# nrf9220_sysctrl register map
Vendor: Nordic Semiconductor; Series: nRF92; File version: 1
Registers are 32-bit, read-write, reset 0x0 unless marked. A register's access mark holds for its fields unless they carry their own. Offsets are from the block's base; [hi:lo] are bit positions; {n}, {i} and the like mark numbered series; 'fields as' and 'values as' point back to an identical list.

## HVBUCK1V8 — Saana HVBUCK register map HVBUCK register map for digital part HVBUCK register map for analog part 0
Base 0x5F97B000
Same registers: HVBUCK1V1 0x5F97C000
0x00 TASKS_START wo — This task will start IP
  [0] TASKS_START
    1=Trigger task
0x04 TASKS_STOP wo — This task will stop IP
  [0] TASKS_STOP
    1=Trigger task
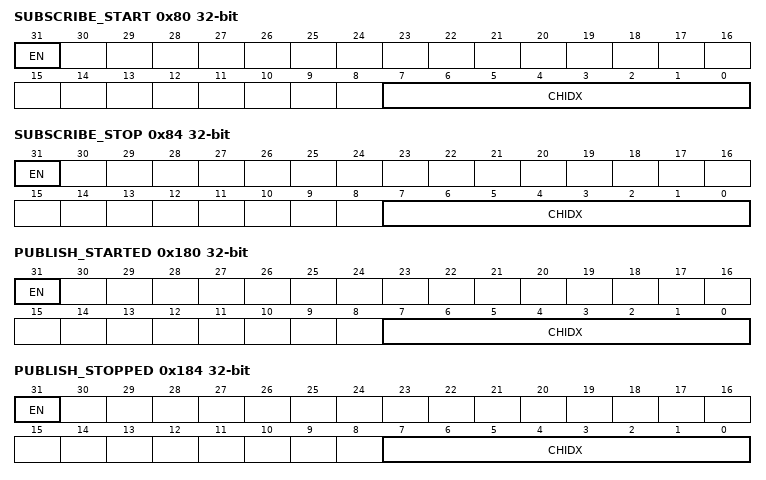
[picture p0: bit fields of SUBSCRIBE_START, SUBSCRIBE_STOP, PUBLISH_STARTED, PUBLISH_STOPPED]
0x80 SUBSCRIBE_START — Subscribe configuration for task START
  [31] EN
    0=Disabled (Disable subscription); 1=Enabled (Enable subscription)
  [7:0] CHIDX — DPPI channel that task START will subscribe to
0x84 SUBSCRIBE_STOP — Subscribe configuration for task STOP
  [31] EN
    values as SUBSCRIBE_START.EN
  [7:0] CHIDX — DPPI channel that task STOP will subscribe to
0x100 EVENTS_STARTED — IP was started
  [0] EVENTS_STARTED
    0=NotGenerated (Event not generated); 1=Generated (Event generated)
0x104 EVENTS_STOPPED — IP was stopped
  [0] EVENTS_STOPPED
    values as EVENTS_STARTED.EVENTS_STARTED
0x180 PUBLISH_STARTED — Publish configuration for event STARTED
  [31] EN
    0=Disabled (Disable publishing); 1=Enabled (Enable publishing)
  [7:0] CHIDX — DPPI channel that event STARTED will publish to
0x184 PUBLISH_STOPPED — Publish configuration for event STOPPED
  [31] EN
    values as PUBLISH_STARTED.EN
  [7:0] CHIDX — DPPI channel that event STOPPED will publish to
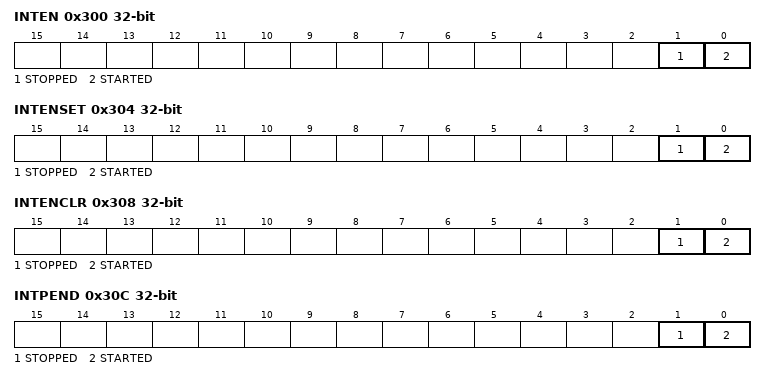
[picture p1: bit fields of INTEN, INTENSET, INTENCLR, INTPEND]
0x300 INTEN — Enable or disable interrupt
  [1] STOPPED — Enable or disable interrupt for event STOPPED
    0=Disabled; 1=Enabled
  [0] STARTED — Enable or disable interrupt for event STARTED
    0=Disabled; 1=Enabled
0x304 INTENSET — Enable interrupt
  [1] STOPPED — Write '1' to enable interrupt for event STOPPED
    on read: 0=Disabled (Read: Disabled); 1=Enabled (Read: Enabled) | on write: 1=Set (Enable)
  [0] STARTED — Write '1' to enable interrupt for event STARTED
    values as STOPPED
0x308 INTENCLR — Disable interrupt
  [1] STOPPED — Write '1' to disable interrupt for event STOPPED
    on read: 0=Disabled (Read: Disabled); 1=Enabled (Read: Enabled) | on write: 1=Clear (Disable)
  [0] STARTED — Write '1' to disable interrupt for event STARTED
    values as STOPPED
0x30C INTPEND ro — Pending interrupts
  [1] STOPPED — Read pending status of interrupt for event STOPPED
    on read: 0=NotPending (Read: Not pending); 1=Pending (Read: Pending)
  [0] STARTED — Read pending status of interrupt for event STARTED
    values as STOPPED
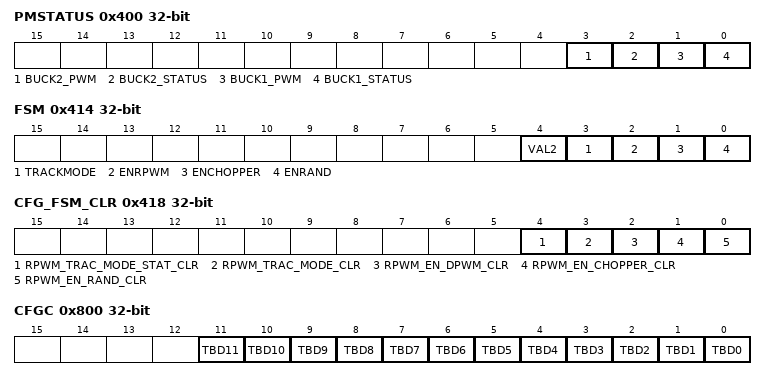
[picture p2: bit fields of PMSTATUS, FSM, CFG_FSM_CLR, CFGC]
0x400 PMSTATUS ro — Power management system status
  [3] BUCK2_PWM — Indicates if BUCK1 is in PWM mode
    0=Hysteretic (Buck1 is idle); 1=PWM (Buck1 is running)
  [2] BUCK2_STATUS — Indicates if BUCK1 is running
    0=Idle (Buck1 is idle); 1=Running (Buck1 is running)
  [1] BUCK1_PWM — Indicates if BUCK1 is in PWM mode
    0=Hysteretic (Buck1 is hysteretic mode); 1=PWM (Buck1 is in PWM)
  [0] BUCK1_STATUS — Indicates if BUCK1 is running
    0=Idle (Buck1 is idle); 1=Running (Buck1 is running)
0x410 STATIC — Voltage target
  [2:0] VAL — Voltage value
0x414 FSM write-1-sets — FSM configs
  [4] VAL2 — Tracking mode selection
  [3] TRACKMODE — Tracking mode selection
    0=TBD0; 1=TBD1
  [2] ENRPWM — Enable digital PWM mode
    0=Disabled (Mode is disabled); 1=Enabled (Mode is enabled)
  [1] ENCHOPPER — Enable for comparator output switching
    0=Disabled (Switching is disabled); 1=Enabled (Switching is enabled)
  [0] ENRAND — Enable for pwm frequency randomization
    0=Disabled (Randomization is disabled); 1=Enabled (Randomization is enabled)
0x418 CFG_FSM_CLR write-1-clears — FSM configs
  [4] RPWM_TRAC_MODE_STAT_CLR — Tracking mode selection
  [3] RPWM_TRAC_MODE_CLR — Tracking mode selection
    0=TBD0; 1=TBD1
  [2] RPWM_EN_DPWM_CLR — Enable digital PWM mode
    0=Disabled (Mode is disabled); 1=Enabled (Mode is enabled)
  [1] RPWM_EN_CHOPPER_CLR — Enable for comparator output switching
    values as FSM.ENCHOPPER
  [0] RPWM_EN_RAND_CLR — Enable for pwm frequency randomization
    values as FSM.ENRAND
0x800 CFGC — Static configuration
  [all] fields
    0=Disabled (Unspecified); 1=Enabled (Unspecified)
  [n] TBD{n} (n=0..11)
0x804 CFG1 — Configuration 1
  [3:0] TBD12
    0=Disabled (Unspecified); 1=Enabled (Unspecified)
0x808 BIASIBPP — IBPP current trimming
  [2:0] VAL — Bias trim value
    0=TBD0; 1=TBD1; 2=TBD2; {v}=TBD{v} (v=4..7)
0x80C BIASIBPSR — IBPSR current trimming
  [4:0] VAL — Bias trim value. The value is 2's complement value from -7.4 percent to 8.0 percent in steps of 0.5 percent
0x810 VOUTHYST — Hysteretic (HYST) output voltage trimming
  [4:0] VAL — Trim value. The value is 2's complement value of 0mV -/+ 8mV steps.
0x814 VOUTPWM — PWM output voltage trimming
  [5:0] VAL — Trim value. The value is 2's complement value of 0mV -/+ 8mV steps.
0x818 VOUTOFFSET — Output voltage offset trimming
  fields as VOUTHYST
0x81C ZCROSS — Zero cross detector trimming
  [3:0] VAL — Trim value. The value is 2's complement value of 0mA +/- 3mA steps.
0x820 HSILIM — HS current limiter trimming
  [2:0] VAL — Trim value. The value is 2's complement value of 0 +/- 8 percent point steps.
0x824 VGND — VGND trim
  [1:0] VAL — Trim value. The value is 2's complement value of +1 percent +/- 2 percent point steps.
0x828 COTTIMER — ????
  [4:0] VAL — ???
0x82C DCOCOARSE — ???
  [0] VAL
0x830 DCOFINE — ???
  [4:0] VAL
0x834 FSMOSC — ???
  [4:0] VAL
0x838 DCOVOUT — ???
  [2:0] VAL
0x83C VOUTHP reset 0x35 — High Power output voltage
  [4:0] VAL — Voltage value. The value is 1.72V + 0.02V steps.
0x840 VOUTLP reset 0x35 — Low Power output voltage
  [4:0] VAL — Voltage value. The value is 1.72V + 0.02V steps.
0x844 HSILIMPROG — HS current limiter program
  [1:0] VAL — HS current limiter value
    0=Val150mA (Current limit to 150mA); 1=Val250mA (Current limit to 250mA); 2=Val350mA (Current limit to 350mA); 3=Val450mA (Current limit to 450mA)
0x848 CLKSTARTDELAY — Duration factor for PWM/RPWM clock start
  [1:0] VAL
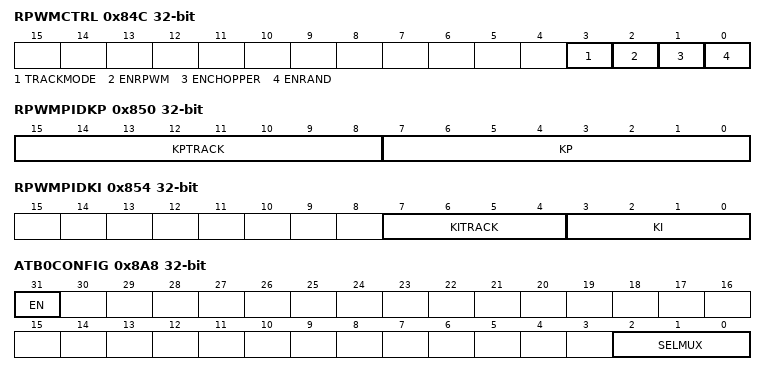
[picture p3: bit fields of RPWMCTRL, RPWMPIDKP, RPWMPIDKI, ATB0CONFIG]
0x84C RPWMCTRL — RPWM control
  [3] TRACKMODE — Tracking mode selection
    0=TBD0; 1=TBD1
  [2] ENRPWM — Enable digital PWM mode
    0=Disabled (Mode is disabled); 1=Enabled (Mode is enabled)
  [1] ENCHOPPER — Enable for comparator output switching
    values as FSM.ENCHOPPER
  [0] ENRAND — Enable for pwm frequency randomization
    values as FSM.ENRAND
0x850 RPWMPIDKP — PID controller protional path gain
  [15:8] KPTRACK — PID controller protional path gain in tracking mode
  [7:0] KP — PID controller protional path gain
0x854 RPWMPIDKI — PID controller integral path gain
  [7:4] KITRACK — PID controller protional path gain in tracking mode
  [3:0] KI — PID controller protional path gain
0x858 RPWMPIDKD — PID controller derivative path gain
  [11:0] KD
0x85C RPWMPIDKF — PID controller derivative path filter gain
  [3:0] KF
0x860 RPWMPIDFILTDIV — PID controller derivative filter scaler
  [3:0] FILTDIV
0x864 RPWMPIDGAINNUM — PID controller gain, numerator part
  [3:0] GAINNUM
0x868 RPWMPIDGAINDIV — PID controller gain, divider part
  [3:0] GAINDIV
0x86C RPWMPIDMAX — Maximum value limiter for PID integrator
  [11:0] MAX
0x870 RPWMPIDINIT — PID controller integral part initial starting value
  [11:0] INIT
0x874 RPWMSTEPS — Value of maximum step in PWM counter
  [5:0] STEPS — Value of maximum step in PWM counter, number of steps will be rpwmSteps+1.
0x878 RPWMFILT — Indicates max width of filtered PWM signal
  [1:0] FILT
0x87C RPWMRANDSCALE — Limits pseudorandom number to this value
  [5:0] SCALE
0x880 RPWMCOMPDELAY — Tunable comparator delay
  [2:0] DELAY
    0=TBD0; 1=TBD1; 2=TBD2; {v}=TBD{v} (v=4..7)
0x884 RPWMTRACDELAY — Determines tracking delay
  [3:0] DELAY
0x888 RPWMOVERLAPDELAY — Unspecified
  [2:0] RPWM_OVERLAP_DELAY
0x88C VCHANGETIME — Unspecified
  [1:0] VAL
0x890 VCHANGEMODEHP — Unspecified
  [0] VAL
0x894 VCHANGEMODELP — Unspecified
  [0] VAL
0x898 OUTPULLD — Unspecified
  [0] VAL
0x89C DCOBLEEDDISABLE — Unspecified
  [0] VAL
0x8A0 ANAEN — Unspecified
  [28:0] ENA
0x8A4 ANAVAL — Unspecified
  [29:0] VAL
0x8A8 ATB0CONFIG — Analog Test Bus 0 (ATB0) configuration
  [31] EN — Enable the analog test bus
    0=Disabled (Analog test bus is disabled); 1=Enabled (Analog test bus is enabled)
  [2:0] SELMUX — Select the signal to be multiplexed to the analog test bus
    0=TBD0; 1=TBD1; 2=TBD2; {v}=TBD{v} (v=4..7)
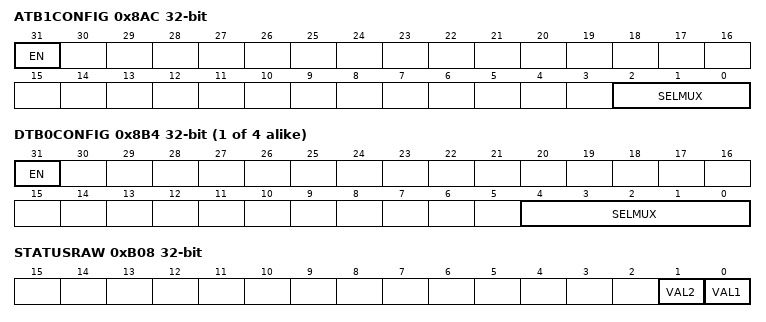
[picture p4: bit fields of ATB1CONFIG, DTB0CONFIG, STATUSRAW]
0x8AC ATB1CONFIG — Analog Test Bus 1 (ATB1) configuration
  fields as ATB0CONFIG
0x8B0 ATBCONFIGRPWM — Analog Test Bus (ATB) configuration for RPWM
  [0] ATB_CONFIG_RPWM
{0x8B4+4i} DTB{i}CONFIG (i=0..3) — Digital Test Bus {i} (DTB{i}) configuration
  [31] EN — Enable the digital test bus
    0=Disabled (Digital test bus is disabled); 1=Enabled (Digital test bus is enabled)
  [4:0] SELMUX — Select the signal to be multiplexed to the digital test bus
    0=TBD0; 1=TBD1; 2=TBD2; {v}=TBD{v} (v=4..7)
0x8C4 DTBCONFIGDCO — Digital Test Bus (DTB) configuration for DCO
  [0] DTB_CONFIG_DCO_EN
0x8C8 TCFG — Test mode configuration
  [15:0] TCFG
0x8CC TCFGRPWM — Test mode configuration for RPWM
  [1:0] TCFG_RPWM
0x8D0 CALEN — Calibration enable
  [0] CAL_EN
    0=ATCMPOff; 1=ATCMPOn
0xB00 RPWMPIDINT ro — PID integrator value
  [11:0] VAL
0xB04 RPWMPIDCTRL ro — PID control word
  [5:0] VAL
0xB08 STATUSRAW ro — Unspecified
  [1] VAL2 — rpwmTracModeStat
  [0] VAL1 — readyRPwmStat
